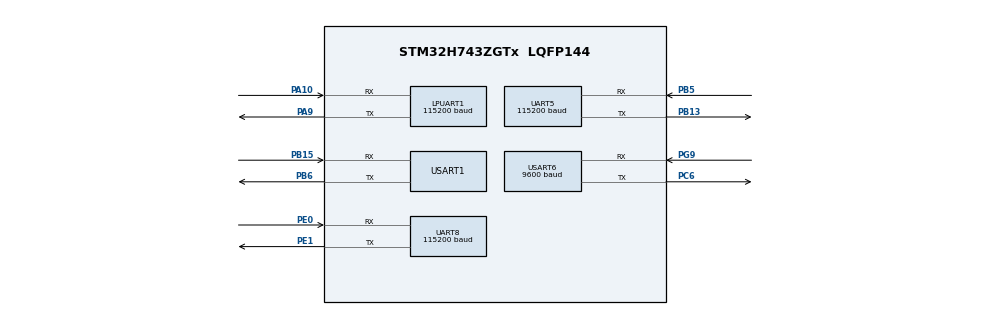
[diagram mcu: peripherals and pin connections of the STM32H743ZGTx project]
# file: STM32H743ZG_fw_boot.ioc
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Dma.Request0=USART1_RX
Dma.Request1=UART5_RX
Dma.UART5_RX.1.Direction=DMA_PERIPH_TO_MEMORY
Dma.UART5_RX.1.EventEnable=DISABLE
Dma.UART5_RX.1.FIFOMode=DMA_FIFOMODE_DISABLE
Dma.UART5_RX.1.Instance=DMA2_Stream2
Dma.UART5_RX.1.MemDataAlignment=DMA_MDATAALIGN_BYTE
Dma.UART5_RX.1.MemInc=DMA_MINC_ENABLE
Dma.UART5_RX.1.Mode=DMA_CIRCULAR
Dma.UART5_RX.1.PeriphDataAlignment=DMA_PDATAALIGN_BYTE
Dma.UART5_RX.1.PeriphInc=DMA_PINC_DISABLE
Dma.UART5_RX.1.Polarity=HAL_DMAMUX_REQ_GEN_RISING
Dma.UART5_RX.1.Priority=DMA_PRIORITY_LOW
Dma.UART5_RX.1.RequestNumber=1
Dma.UART5_RX.1.SignalID=NONE
Dma.UART5_RX.1.SyncEnable=DISABLE
Dma.UART5_RX.1.SyncPolarity=HAL_DMAMUX_SYNC_NO_EVENT
Dma.UART5_RX.1.SyncRequestNumber=1
Dma.UART5_RX.1.SyncSignalID=NONE
Dma.USART1_RX.0.Direction=DMA_PERIPH_TO_MEMORY
Dma.USART1_RX.0.EventEnable=DISABLE
Dma.USART1_RX.0.FIFOMode=DMA_FIFOMODE_DISABLE
Dma.USART1_RX.0.Instance=DMA1_Stream0
Dma.USART1_RX.0.MemDataAlignment=DMA_MDATAALIGN_BYTE
Dma.USART1_RX.0.MemInc=DMA_MINC_ENABLE
Dma.USART1_RX.0.Mode=DMA_CIRCULAR
Dma.USART1_RX.0.PeriphDataAlignment=DMA_PDATAALIGN_BYTE
Dma.USART1_RX.0.PeriphInc=DMA_PINC_DISABLE
Dma.USART1_RX.0.Polarity=HAL_DMAMUX_REQ_GEN_RISING
Dma.USART1_RX.0.Priority=DMA_PRIORITY_LOW
Dma.USART1_RX.0.RequestNumber=1
Dma.USART1_RX.0.SignalID=NONE
Dma.USART1_RX.0.SyncEnable=DISABLE
Dma.USART1_RX.0.SyncPolarity=HAL_DMAMUX_SYNC_NO_EVENT
Dma.USART1_RX.0.SyncRequestNumber=1
Dma.USART1_RX.0.SyncSignalID=NONE
FREERTOS.Queues01=gyroQueue,256,uint32_t,0,Dynamic,NULL,NULL
FREERTOS.Tasks01=TaskDebug,24,512,DebugTask,As weak,NULL,Static,TaskDebugBuffer,TaskDebugControlBlock;TaskSensing,16,512,SensingTask,As weak,NULL,Static,TaskSensingBuffer,TaskSensingControlBlock;TaskMain,16,1024,MainTask,As weak,NULL,Static,TaskMainBuffer,TaskMainControlBlock
FREERTOS.configUSE_NEWLIB_REENTRANT=1
LPUART1.BaudRate=115200
Mcu.Family=STM32H7
Mcu.Name=STM32H743ZGTx
Mcu.Package=LQFP144
NVIC.DMA1_Stream0_IRQn=true\:5\:0\:false\:false\:true\:true\:false\:true\:true
NVIC.DMA2_Stream2_IRQn=true\:5\:0\:false\:false\:true\:true\:false\:true\:true
NVIC.PriorityGroup=NVIC_PRIORITYGROUP_4
NVIC.TIM1_UP_IRQn=true\:15\:0\:true\:false\:true\:false\:false\:true\:true
NVIC.TimeBase=TIM1_UP_IRQn
NVIC.TimeBaseIP=TIM1
NVIC.UART5_IRQn=true\:5\:0\:false\:false\:true\:true\:true\:true\:true
NVIC.UART8_IRQn=true\:5\:0\:false\:false\:true\:true\:true\:true\:true
NVIC.USART1_IRQn=true\:5\:0\:false\:false\:true\:true\:true\:true\:true
NVIC.USART6_IRQn=true\:5\:0\:false\:false\:true\:true\:true\:true\:true
PA10.Mode=Asynchronous
PA10.Signal=LPUART1_RX
PA9.Mode=Asynchronous
PA9.Signal=LPUART1_TX
PB13.Mode=Asynchronous
PB13.Signal=UART5_TX
PB15.Mode=Asynchronous
PB15.Signal=USART1_RX
PB5.GPIO_PuPd=GPIO_NOPULL
PB5.Mode=Asynchronous
PB5.Signal=UART5_RX
PB6.Mode=Asynchronous
PB6.Signal=USART1_TX
PC6.Mode=Asynchronous
PC6.Signal=USART6_TX
PE0.GPIO_PuPd=GPIO_PULLUP
PE0.GPIO_Speed=GPIO_SPEED_FREQ_HIGH
PE0.Mode=Asynchronous
PE0.Signal=UART8_RX
PE1.GPIO_PuPd=GPIO_PULLUP
PE1.GPIO_Speed=GPIO_SPEED_FREQ_HIGH
PE1.Mode=Asynchronous
PE1.Signal=UART8_TX
PG9.Mode=Asynchronous
PG9.Signal=USART6_RX
PH0-OSC_IN\ (PH0).Mode=HSE-External-Oscillator
PH0-OSC_IN\ (PH0).Signal=RCC_OSC_IN
PH1-OSC_OUT\ (PH1).Mode=HSE-External-Oscillator
PH1-OSC_OUT\ (PH1).Signal=RCC_OSC_OUT
ProjectManager.HeapSize=0x200
ProjectManager.StackSize=0x400
ProjectManager.TargetToolchain=STM32CubeIDE
RCC.ADCFreq_Value=50390625
RCC.APB1Freq_Value=30000000
RCC.APB2Freq_Value=30000000
RCC.APB3Freq_Value=30000000
RCC.APB4Freq_Value=60000000
RCC.CortexFreq_Value=120000000
RCC.D1PPRE=RCC_APB3_DIV2
RCC.D2PPRE1=RCC_APB1_DIV2
RCC.D2PPRE2=RCC_APB2_DIV2
RCC.DIVM1=5
RCC.DIVN1=48
RCC.DIVQ1=5
RCC.HCLKFreq_Value=60000000
RCC.HPRE=RCC_HCLK_DIV2
RCC.PLL2FRACN=0
RCC.PLL3FRACN=0
RCC.PLLFRACN=0
RCC.PLLSourceVirtual=RCC_PLLSOURCE_HSE
RCC.SYSCLKFreq_VALUE=120000000
RCC.SYSCLKSource=RCC_SYSCLKSOURCE_PLLCLK
RCC.USBFreq_Value=48000000
UART5.BaudRate=115200
UART5.FIFOMode=FIFOMODE_DISABLE
UART8.BaudRate=115200
USART1.VirtualMode-Asynchronous=VM_ASYNC
USART6.BaudRate=9600
USART6.VirtualMode-Asynchronous=VM_ASYNC
VP_FREERTOS_VS_CMSIS_V2.Mode=CMSIS_V2
VP_RTC_VS_RTC_Activate.Mode=RTC_Enabled
VP_SYS_VS_tim1.Mode=TIM1
board=custom

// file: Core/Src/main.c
/* USER CODE BEGIN Header */
/**
  ******************************************************************************
  * @file           : main.c
  * @brief          : Main program body
  ******************************************************************************
  * @attention
  *
  * <h2><center>&copy; Copyright (c) 2021 STMicroelectronics.
  * All rights reserved.</center></h2>
  *
  * This software component is licensed by ST under BSD 3-Clause license,
  * the "License"; You may not use this file except in compliance with the
  * License. You may obtain a copy of the License at:
  *                        opensource.org/licenses/BSD-3-Clause
  *
  ******************************************************************************
  */
/* USER CODE END Header */
#include "main.h"
#include "cmsis_os.h"

typedef StaticTask_t osStaticThreadDef_t;

UART_HandleTypeDef hlpuart1;
UART_HandleTypeDef huart5;
UART_HandleTypeDef huart8;
UART_HandleTypeDef huart1;
UART_HandleTypeDef huart6;
DMA_HandleTypeDef hdma_uart5_rx;
DMA_HandleTypeDef hdma_usart1_rx;

RTC_HandleTypeDef hrtc;

/* Definitions for TaskDebug */
osThreadId_t TaskDebugHandle;
uint32_t TaskDebugBuffer[ 512 ];
osStaticThreadDef_t TaskDebugControlBlock;
const osThreadAttr_t TaskDebug_attributes = {
  .name = "TaskDebug",
  .cb_mem = &TaskDebugControlBlock,
  .cb_size = sizeof(TaskDebugControlBlock),
  .stack_mem = &TaskDebugBuffer[0],
  .stack_size = sizeof(TaskDebugBuffer),
  .priority = (osPriority_t) osPriorityNormal,
};
/* Definitions for TaskSensing */
osThreadId_t TaskSensingHandle;
uint32_t TaskSensingBuffer[ 512 ];
osStaticThreadDef_t TaskSensingControlBlock;
const osThreadAttr_t TaskSensing_attributes = {
  .name = "TaskSensing",
  .cb_mem = &TaskSensingControlBlock,
  .cb_size = sizeof(TaskSensingControlBlock),
  .stack_mem = &TaskSensingBuffer[0],
  .stack_size = sizeof(TaskSensingBuffer),
  .priority = (osPriority_t) osPriorityBelowNormal,
};
/* Definitions for TaskMain */
osThreadId_t TaskMainHandle;
uint32_t TaskMainBuffer[ 1024 ];
osStaticThreadDef_t TaskMainControlBlock;
const osThreadAttr_t TaskMain_attributes = {
  .name = "TaskMain",
  .cb_mem = &TaskMainControlBlock,
  .cb_size = sizeof(TaskMainControlBlock),
  .stack_mem = &TaskMainBuffer[0],
  .stack_size = sizeof(TaskMainBuffer),
  .priority = (osPriority_t) osPriorityBelowNormal,
};
/* Definitions for gyroQueue */
osMessageQueueId_t gyroQueueHandle;
const osMessageQueueAttr_t gyroQueue_attributes = {
  .name = "gyroQueue"
};

void SystemClock_Config(void);
static void MX_GPIO_Init(void);
static void MX_UART8_Init(void);
static void MX_USART6_UART_Init(void);
static void MX_UART5_Init(void);
static void MX_DMA_Init(void);
static void MX_USART1_UART_Init(void);
static void MX_LPUART1_UART_Init(void);
static void MX_RTC_Init(void);
void DebugTask(void *argument);
void SensingTask(void *argument);
void MainTask(void *argument);

int main(void)
{

  /* MCU Configuration--------------------------------------------------------*/

  /* Reset of all peripherals, Initializes the Flash interface and the Systick. */
  HAL_Init();

  /* Configure the system clock */
  SystemClock_Config();

  /* Initialize all configured peripherals */
  MX_GPIO_Init();
  MX_UART8_Init();
  MX_USART6_UART_Init();
  MX_UART5_Init();
  MX_DMA_Init();
  MX_USART1_UART_Init();
  MX_LPUART1_UART_Init();
  MX_RTC_Init();
  /* USER CODE BEGIN 2 */

//  HAL_UART_Receive_DMA(&huart6, rxBuffer, 100);
//  HAL_UART_Receive_DMA(&huart5, rxBuffer, 100);
//  HAL_UART_Transmit_DMA(&huart8, rxBuffer, 100);
  /* USER CODE END 2 */

  /* Init scheduler */
  osKernelInitialize();

  /* Create the queue(s) */
  /* creation of gyroQueue */
  gyroQueueHandle = osMessageQueueNew (256, sizeof(uint32_t), &gyroQueue_attributes);

  /* Create the thread(s) */
  /* creation of TaskDebug */
  TaskDebugHandle = osThreadNew(DebugTask, NULL, &TaskDebug_attributes);

  /* creation of TaskSensing */
  TaskSensingHandle = osThreadNew(SensingTask, NULL, &TaskSensing_attributes);

  /* creation of TaskMain */
  TaskMainHandle = osThreadNew(MainTask, NULL, &TaskMain_attributes);

  /* Start scheduler */
  osKernelStart();

  /* We should never get here as control is now taken by the scheduler */
  /* Infinite loop */
  while (1)
  {

  }
}

void SystemClock_Config(void)
{
  RCC_OscInitTypeDef RCC_OscInitStruct = {0};
  RCC_ClkInitTypeDef RCC_ClkInitStruct = {0};

  /** Supply configuration update enable
  */
  HAL_PWREx_ConfigSupply(PWR_LDO_SUPPLY);

  /** Configure the main internal regulator output voltage
  */
  __HAL_PWR_VOLTAGESCALING_CONFIG(PWR_REGULATOR_VOLTAGE_SCALE3);

  while(!__HAL_PWR_GET_FLAG(PWR_FLAG_VOSRDY)) {}

  /** Initializes the RCC Oscillators according to the specified parameters
  * in the RCC_OscInitTypeDef structure.
  */
  RCC_OscInitStruct.OscillatorType = RCC_OSCILLATORTYPE_LSI|RCC_OSCILLATORTYPE_HSE;
  RCC_OscInitStruct.HSEState = RCC_HSE_ON;
  RCC_OscInitStruct.LSIState = RCC_LSI_ON;
  RCC_OscInitStruct.PLL.PLLState = RCC_PLL_ON;
  RCC_OscInitStruct.PLL.PLLSource = RCC_PLLSOURCE_HSE;
  RCC_OscInitStruct.PLL.PLLM = 5;
  RCC_OscInitStruct.PLL.PLLN = 48;
  RCC_OscInitStruct.PLL.PLLP = 2;
  RCC_OscInitStruct.PLL.PLLQ = 5;
  RCC_OscInitStruct.PLL.PLLR = 2;
  RCC_OscInitStruct.PLL.PLLRGE = RCC_PLL1VCIRANGE_2;
  RCC_OscInitStruct.PLL.PLLVCOSEL = RCC_PLL1VCOWIDE;
  RCC_OscInitStruct.PLL.PLLFRACN = 0;
  if (HAL_RCC_OscConfig(&RCC_OscInitStruct) != HAL_OK)
  {
    Error_Handler();
  }

  /** Initializes the CPU, AHB and APB buses clocks
  */
  RCC_ClkInitStruct.ClockType = RCC_CLOCKTYPE_HCLK|RCC_CLOCKTYPE_SYSCLK
                              |RCC_CLOCKTYPE_PCLK1|RCC_CLOCKTYPE_PCLK2
                              |RCC_CLOCKTYPE_D3PCLK1|RCC_CLOCKTYPE_D1PCLK1;
  RCC_ClkInitStruct.SYSCLKSource = RCC_SYSCLKSOURCE_PLLCLK;
  RCC_ClkInitStruct.SYSCLKDivider = RCC_SYSCLK_DIV1;
  RCC_ClkInitStruct.AHBCLKDivider = RCC_HCLK_DIV2;
  RCC_ClkInitStruct.APB3CLKDivider = RCC_APB3_DIV2;
  RCC_ClkInitStruct.APB1CLKDivider = RCC_APB1_DIV2;
  RCC_ClkInitStruct.APB2CLKDivider = RCC_APB2_DIV2;
  RCC_ClkInitStruct.APB4CLKDivider = RCC_APB4_DIV1;

  if (HAL_RCC_ClockConfig(&RCC_ClkInitStruct, FLASH_LATENCY_1) != HAL_OK)
  {
    Error_Handler();
  }
}

static void MX_LPUART1_UART_Init(void)
{

  hlpuart1.Instance = LPUART1;
  hlpuart1.Init.BaudRate = 115200;
  hlpuart1.Init.WordLength = UART_WORDLENGTH_8B;
  hlpuart1.Init.StopBits = UART_STOPBITS_1;
  hlpuart1.Init.Parity = UART_PARITY_NONE;
  hlpuart1.Init.Mode = UART_MODE_TX_RX;
  hlpuart1.Init.HwFlowCtl = UART_HWCONTROL_NONE;
  hlpuart1.Init.OneBitSampling = UART_ONE_BIT_SAMPLE_DISABLE;
  hlpuart1.Init.ClockPrescaler = UART_PRESCALER_DIV1;
  hlpuart1.AdvancedInit.AdvFeatureInit = UART_ADVFEATURE_NO_INIT;
  hlpuart1.FifoMode = UART_FIFOMODE_DISABLE;
  if (HAL_UART_Init(&hlpuart1) != HAL_OK)
  {
    Error_Handler();
  }
  if (HAL_UARTEx_SetTxFifoThreshold(&hlpuart1, UART_TXFIFO_THRESHOLD_1_8) != HAL_OK)
  {
    Error_Handler();
  }
  if (HAL_UARTEx_SetRxFifoThreshold(&hlpuart1, UART_RXFIFO_THRESHOLD_1_8) != HAL_OK)
  {
    Error_Handler();
  }
  if (HAL_UARTEx_DisableFifoMode(&hlpuart1) != HAL_OK)
  {
    Error_Handler();
  }

}

static void MX_UART5_Init(void)
{

  huart5.Instance = UART5;
  huart5.Init.BaudRate = 115200;
  huart5.Init.WordLength = UART_WORDLENGTH_8B;
  huart5.Init.StopBits = UART_STOPBITS_1;
  huart5.Init.Parity = UART_PARITY_NONE;
  huart5.Init.Mode = UART_MODE_TX_RX;
  huart5.Init.HwFlowCtl = UART_HWCONTROL_NONE;
  huart5.Init.OverSampling = UART_OVERSAMPLING_16;
  huart5.Init.OneBitSampling = UART_ONE_BIT_SAMPLE_DISABLE;
  huart5.Init.ClockPrescaler = UART_PRESCALER_DIV1;
  huart5.AdvancedInit.AdvFeatureInit = UART_ADVFEATURE_NO_INIT;
  if (HAL_UART_Init(&huart5) != HAL_OK)
  {
    Error_Handler();
  }
  if (HAL_UARTEx_SetTxFifoThreshold(&huart5, UART_TXFIFO_THRESHOLD_1_8) != HAL_OK)
  {
    Error_Handler();
  }
  if (HAL_UARTEx_SetRxFifoThreshold(&huart5, UART_RXFIFO_THRESHOLD_1_8) != HAL_OK)
  {
    Error_Handler();
  }
  if (HAL_UARTEx_DisableFifoMode(&huart5) != HAL_OK)
  {
    Error_Handler();
  }

}

static void MX_UART8_Init(void)
{

  huart8.Instance = UART8;
  huart8.Init.BaudRate = 115200;
  huart8.Init.WordLength = UART_WORDLENGTH_8B;
  huart8.Init.StopBits = UART_STOPBITS_1;
  huart8.Init.Parity = UART_PARITY_NONE;
  huart8.Init.Mode = UART_MODE_TX_RX;
  huart8.Init.HwFlowCtl = UART_HWCONTROL_NONE;
  huart8.Init.OverSampling = UART_OVERSAMPLING_16;
  huart8.Init.OneBitSampling = UART_ONE_BIT_SAMPLE_DISABLE;
  huart8.Init.ClockPrescaler = UART_PRESCALER_DIV1;
  huart8.AdvancedInit.AdvFeatureInit = UART_ADVFEATURE_NO_INIT;
  if (HAL_UART_Init(&huart8) != HAL_OK)
  {
    Error_Handler();
  }
  if (HAL_UARTEx_SetTxFifoThreshold(&huart8, UART_TXFIFO_THRESHOLD_1_8) != HAL_OK)
  {
    Error_Handler();
  }
  if (HAL_UARTEx_SetRxFifoThreshold(&huart8, UART_RXFIFO_THRESHOLD_1_8) != HAL_OK)
  {
    Error_Handler();
  }
  if (HAL_UARTEx_DisableFifoMode(&huart8) != HAL_OK)
  {
    Error_Handler();
  }

}

static void MX_USART1_UART_Init(void)
{

  huart1.Instance = USART1;
  huart1.Init.BaudRate = 115200;
  huart1.Init.WordLength = UART_WORDLENGTH_8B;
  huart1.Init.StopBits = UART_STOPBITS_1;
  huart1.Init.Parity = UART_PARITY_NONE;
  huart1.Init.Mode = UART_MODE_TX_RX;
  huart1.Init.HwFlowCtl = UART_HWCONTROL_NONE;
  huart1.Init.OverSampling = UART_OVERSAMPLING_16;
  huart1.Init.OneBitSampling = UART_ONE_BIT_SAMPLE_DISABLE;
  huart1.Init.ClockPrescaler = UART_PRESCALER_DIV1;
  huart1.AdvancedInit.AdvFeatureInit = UART_ADVFEATURE_NO_INIT;
  if (HAL_UART_Init(&huart1) != HAL_OK)
  {
    Error_Handler();
  }
  if (HAL_UARTEx_SetTxFifoThreshold(&huart1, UART_TXFIFO_THRESHOLD_1_8) != HAL_OK)
  {
    Error_Handler();
  }
  if (HAL_UARTEx_SetRxFifoThreshold(&huart1, UART_RXFIFO_THRESHOLD_1_8) != HAL_OK)
  {
    Error_Handler();
  }
  if (HAL_UARTEx_DisableFifoMode(&huart1) != HAL_OK)
  {
    Error_Handler();
  }

}

static void MX_USART6_UART_Init(void)
{

  huart6.Instance = USART6;
  huart6.Init.BaudRate = 9600;
  huart6.Init.WordLength = UART_WORDLENGTH_8B;
  huart6.Init.StopBits = UART_STOPBITS_1;
  huart6.Init.Parity = UART_PARITY_NONE;
  huart6.Init.Mode = UART_MODE_TX_RX;
  huart6.Init.HwFlowCtl = UART_HWCONTROL_NONE;
  huart6.Init.OverSampling = UART_OVERSAMPLING_16;
  huart6.Init.OneBitSampling = UART_ONE_BIT_SAMPLE_DISABLE;
  huart6.Init.ClockPrescaler = UART_PRESCALER_DIV1;
  huart6.AdvancedInit.AdvFeatureInit = UART_ADVFEATURE_NO_INIT;
  if (HAL_UART_Init(&huart6) != HAL_OK)
  {
    Error_Handler();
  }
  if (HAL_UARTEx_SetTxFifoThreshold(&huart6, UART_TXFIFO_THRESHOLD_1_8) != HAL_OK)
  {
    Error_Handler();
  }
  if (HAL_UARTEx_SetRxFifoThreshold(&huart6, UART_RXFIFO_THRESHOLD_1_8) != HAL_OK)
  {
    Error_Handler();
  }
  if (HAL_UARTEx_DisableFifoMode(&huart6) != HAL_OK)
  {
    Error_Handler();
  }

}

static void MX_RTC_Init(void)
{

  /** Initialize RTC Only
  */
  hrtc.Instance = RTC;
  hrtc.Init.HourFormat = RTC_HOURFORMAT_24;
  hrtc.Init.AsynchPrediv = 127;
  hrtc.Init.SynchPrediv = 255;
  hrtc.Init.OutPut = RTC_OUTPUT_DISABLE;
  hrtc.Init.OutPutPolarity = RTC_OUTPUT_POLARITY_HIGH;
  hrtc.Init.OutPutType = RTC_OUTPUT_TYPE_OPENDRAIN;
  hrtc.Init.OutPutRemap = RTC_OUTPUT_REMAP_NONE;
  if (HAL_RTC_Init(&hrtc) != HAL_OK)
  {
    Error_Handler();
  }

}

static void MX_DMA_Init(void)
{

  /* DMA controller clock enable */
  __HAL_RCC_DMA1_CLK_ENABLE();
  __HAL_RCC_DMA2_CLK_ENABLE();

  /* DMA interrupt init */
  /* DMA1_Stream0_IRQn interrupt configuration */
  HAL_NVIC_SetPriority(DMA1_Stream0_IRQn, 5, 0);
  HAL_NVIC_EnableIRQ(DMA1_Stream0_IRQn);
  /* DMA2_Stream2_IRQn interrupt configuration */
  HAL_NVIC_SetPriority(DMA2_Stream2_IRQn, 5, 0);
  HAL_NVIC_EnableIRQ(DMA2_Stream2_IRQn);

}

static void MX_GPIO_Init(void)
{

  /* GPIO Ports Clock Enable */
  __HAL_RCC_GPIOH_CLK_ENABLE();
  __HAL_RCC_GPIOB_CLK_ENABLE();
  __HAL_RCC_GPIOC_CLK_ENABLE();
  __HAL_RCC_GPIOA_CLK_ENABLE();
  __HAL_RCC_GPIOG_CLK_ENABLE();
  __HAL_RCC_GPIOE_CLK_ENABLE();

}

/* USER CODE BEGIN 4 */
__weak void HAL_UART_RxCpltCallback(UART_HandleTypeDef *huart){

}

//PUTCHAR_PROTOTYPE
//{
//  HAL_UART_Transmit(&huart8, (uint8_t *)&ch, 1, HAL_MAX_DELAY);
//  return ch;
//}
/* USER CODE END 4 */

__weak void DebugTask(void *argument)
{
  /* USER CODE BEGIN 5 */
//  /* Infinite loop */
//  for(;;)
//  {
//
//    osDelay(1);
//  }
  /* USER CODE END 5 */
}

__weak void SensingTask(void *argument)
{
  for(;;)
  {
    osDelay(1);
  }
}

__weak void MainTask(void *argument)
{
  for(;;)
  {
    osDelay(1);
  }
}

void HAL_TIM_PeriodElapsedCallback(TIM_HandleTypeDef *htim)
{
  if (htim->Instance == TIM1) {
    HAL_IncTick();
  }
}

void Error_Handler(void)
{
  __disable_irq();
  while (1)
  {
  }
}
